# cslr_uhpi register map
Vendor: Texas Instruments
Peripheral module from a debugger description file (folder C5517).
Address unit: 16 bits
Registers are 16-bit, read-only, reset 0x0 unless marked. A register's access mark holds for its fields unless they carry their own. Offsets are as the file gives them; lines under a group give offsets from that group; [hi:lo] are bit positions; {n}, {i} and the like mark numbered series; 'fields as' and 'values as' point back to an identical list; <NAME> marks a mode.

## UHPI — Parallel port interface for accessing CPU s memory space by external host processor.
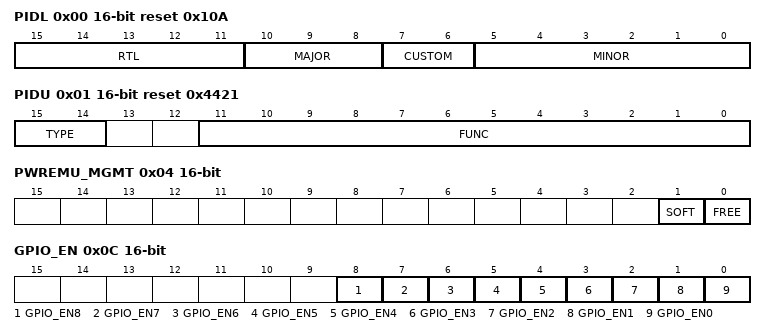
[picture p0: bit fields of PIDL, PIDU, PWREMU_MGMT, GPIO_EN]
0x00 PIDL reset 0x10A — This Register stores versioning information used to identify the specific UHPI peripheral implemented in a particular device
  [15:11] RTL — RTL Version.
  [10:8] MAJOR — Major Revision. 001b for module releases corresponding to this functional spec.
  [7:6] CUSTOM — Non-custom.
  [5:0] MINOR — Minor Revision. 001010b for module releases corresponding to this functional spec.
0x01 PIDU access not given reset 0x4421 — This Register stores versioning information used to identify the specific UHPI peripheral implemented in a particular device
  [15:14] TYPE ro — Used to distinguish between old Scheme and current. Spare bit to encode future schemes.
  [11:0] FUNC ro — Function. 421h for UHPI.
0x04 PWREMU_MGMT access not given — This Register control the operation of the peripheral during emulation suspend and / or idle states
  [1] SOFT rw — Emulation Suspend bit
    0=DISABLE (Upon emulation suspend the peripheral operation is not affected.); 1=ENABLE (Upon emulation suspend current host and Vbus operations will complete, after which the Vbus interfaces will remain in the idle state)
  [0] FREE rw — Free run mode operation bit
    0=DISABLE (SOFT bit takes effect); 1=ENABLE (Upon emulation suspend the peripheral operation will not be affected (regardless of SOFT).)
0x08 GPINT_CTRLL access not given — GPIO interrupts control Register lower
  [2] GPINT_EN rw — GPIO Interrupt Enable bit
    0=DISABLE (Enabled /HAS as a GPINT sourcing the CPU Interrupt); 1=ENABLE (Disabled /HAS as a GPINT sourcing the CPU Interrupt)
0x09 GPINT_CTRLU access not given — GPIO interrupts control Register Upper
  [2] GPINT_INV rw — GPINT Invert bit
    0=DISABLE (GPINT not inverted); 1=ENABLE (GPINT inverted)
0x0C GPIO_EN access not given — GPIO enable Register
  [8] GPIO_EN8 rw — GPIO Enable bit 8
    0=DISABLE (HD[15:8] pins will work as HPI.); 1=ENABLE (HD[15:8] pins will work as GPIO.)
  [7] GPIO_EN7 rw — GPIO Enable bit 7
    0=DISABLE (HD[7:0] pins will work as HPI.); 1=ENABLE (HD[7:0] pins will work as GPIO.)
  [6] GPIO_EN6 rw — GPIO Enable bit 6
    0=DISABLE (/HINT pin will work as HPI.); 1=ENABLE (/HINT pin will work as GPIO.)
  [5] GPIO_EN5 rw — GPIO Enable bit 5
    0=DISABLE (HRDY and /HRDY pins will work as HPI.); 1=ENABLE (HRDY and /HRDY pins will work as GPIO.)
  [4] GPIO_EN4 rw — GPIO Enable bit 4
    0=DISABLE (HHWIL pin will work as HPI.); 1=ENABLE (HHWIL pin will work as GPIO.)
  [3] GPIO_EN3 rw — GPIO Enable bit 3
    0=DISABLE (/HBE[3:0] pins will work as HPI.); 1=ENABLE (/HBE[3:0] pins will work as GPIO.)
  [2] GPIO_EN2 rw — GPIO Enable bit 2
    0=DISABLE (/HAS pin will work as HPI.); 1=ENABLE (/HAS pin will work as GPIO.)
  [1] GPIO_EN1 rw — GPIO Enable bit 1
    0=DISABLE (HCNTL[B:A] pins will work as HPI.); 1=ENABLE (HCNTL[B:A] pins will work as GPIO.)
  [0] GPIO_EN0 rw — GPIO Enable bit 0
    0=DISABLE (/HCS, /HDS1, /HDS2 and HR/W pins will work as HPI.); 1=ENABLE (/HCS, /HDS1, /HDS2 and HR/W pins will work as GPIO.)
0x10 GPIO_DIR1 rw — GPIO direction control Register
  [15:0] DIR — The DIR bits control the direction of the HD[15:0] pins when they are configured as general purpose I/O. DIRx=1 configures the HDx pin as an output and DIRx=0 configures theHDx pin as an input.
0x14 GPIO_DAT1 rw — GPIO Data Register
  [15:0] DAT — The value written in this will reflect on HD[15:0], when configured as output.And will read the logical level on the pin when configured as input.
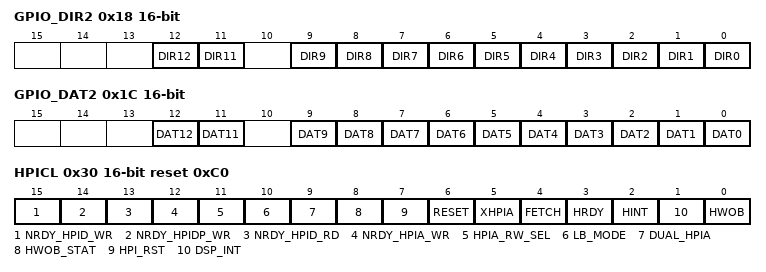
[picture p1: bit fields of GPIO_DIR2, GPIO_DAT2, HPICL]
0x18 GPIO_DIR2 access not given — GPIO direction control Register
  [12] DIR12 rw — Direction control for /HBE1 pin when configured as GPIO
    1=OUTPUT (/HBE1 pin configured as output.); 0=INPUT (/HBE1 pin configured as input.)
  [11] DIR11 rw — Direction control for /HBE0 pin when configured as GPIO
    1=OUTPUT (/HBE0 pin configured as output.); 0=INPUT (/HBE0 pin configured as input.)
  [9] DIR9 rw — Direction control for HRDY pin when configured as GPIO
    1=OUTPUT (HRDY pin configured as output.); 0=INPUT (/HRDY pin configured as input.)
  [8] DIR8 rw — Direction control for /HINT pin when configured as GPIO
    1=OUTPUT (/HINT pin configured as output.); 0=INPUT (HRDY pin configured as input.)
  [7] DIR7 rw — Direction control for HCNTLA pin when configured as GPIO
    1=OUTPUT (HCNTLA pin configured as output.); 0=INPUT (/HINT pin configured as input.)
  [6] DIR6 rw — Direction control for HCNTLB pin when configured as GPIO
    1=OUTPUT (HCNTLB pin configured as output.); 0=INPUT (HCNTLA pin configured as input.)
  [5] DIR5 rw — Direction control for HHWIL pin when configured as GPIO
    1=OUTPUT (HHWIL pin configured as output.); 0=INPUT (HCNTLB pin configured as input.)
  [4] DIR4 rw — Direction control for HR/W pin when configured as GPIO
    1=OUTPUT (HR/W pin configured as output.); 0=INPUT (HHWIL pin configured as input.)
  [3] DIR3 rw — Direction control for /HDS2 pin when configured as GPIO
    1=OUTPUT (/HDS2 pin configured as output.); 0=INPUT (HR/W pin configured as input.)
  [2] DIR2 rw — Direction control for /HDS1 pin when configured as GPIO
    1=OUTPUT (/HDS1 pin configured as output.); 0=INPUT (/HDS2 pin configured as input.)
  [1] DIR1 rw — Direction control for /HCS pin when configured as GPIO
    1=OUTPUT (/HCS pin configured as output.); 0=INPUT (/HDS1 pin configured as input.)
  [0] DIR0 rw — Direction control for /HAS pin when configured as GPIO
    1=OUTPUT (/HAS pin configured as output.); 0=INPUT (/HCS pin configured as input.)
0x1C GPIO_DAT2 access not given — GPIO Data Register
  [12] DAT12 rw — Controls the output level of the /HBE1 pin when configured as output and reads the status of /HBE1 when configured as input
    1=HIGH (/HBE1 pin is at logical high or driven high); 0=LOW (/HBE2 pin is at logical low or driven low)
  [11] DAT11 rw — Controls the output level of the /HBE0 pin when configured as output and reads the status of /HBE0 when configured as input
    1=HIGH (/HBE0 pin is at logical high or driven high); 0=LOW (/HBE1 pin is at logical low or driven low)
  [9] DAT9 rw — Controls the output level of the HRDY pin when configured as output and reads the status of HRDY when configured as input
    1=HIGH (HRDY pin is at logical high or driven high); 0=LOW (/HRDY pin is at logical low or driven low)
  [8] DAT8 rw — Controls the output level of the /HINT pin when configured as output and reads the status of /HINT when configured as input
    1=HIGH (/HINTpin is at logical high or driven high); 0=LOW (HRDY pin is at logical low or driven low)
  [7] DAT7 rw — Controls the output level of the HCNTLA pin when configured as output and reads the status of HCNTLA when configured as input
    1=HIGH (HCNTLA pin is at logical high or driven high); 0=LOW (/HINT pin is at logical low or driven low)
  [6] DAT6 rw — Controls the output level of the HCNTLB pin when configured as output and reads the status of HCNTLB when configured as input
    1=HIGH (HCNTLB pin is at logical high or driven high); 0=LOW (HCNTLA pin is at logical low or driven low)
  [5] DAT5 rw — Controls the output level of the HHWIL pin when configured as output and reads the status of HHWIL when configured as input
    1=HIGH (HHWIL pin is at logical high or driven high); 0=LOW (HCNTLB pin is at logical low or driven low)
  [4] DAT4 rw — Controls the output level of the HR/W pin when configured as output and reads the status of HR/W when configured as input
    1=HIGH (HR/W pin is at logical high or driven high); 0=LOW (HHWIL pin is at logical low or driven low)
  [3] DAT3 rw — Controls the output level of the /HDS2 pin when configured as output and reads the status of /HDS2 when configured as input
    1=HIGH (/HDS2 pin is at logical high or driven high); 0=LOW (HR/W pin is at logical low or driven low)
  [2] DAT2 rw — Controls the output level of the /HDS1 pin when configured as output and reads the status of /HDS1 when configured as input
    1=HIGH (/HDS1 pin is at logical high or driven high); 0=LOW (/HDS2 pin is at logical low or driven low)
  [1] DAT1 rw — Controls the output level of the /HCS pin when configured as output and reads the status of /HCS when configured as input
    1=HIGH (/HCS pin is at logical high or driven high); 0=LOW (/HDS1 pin is at logical low or driven low)
  [0] DAT0 rw — Controls the output level of the /HAS pin when configured as output and reads the status of /HAS when configured as input
    1=HIGH (/HAS pin is at logical high or driven high); 0=LOW (/HCS pin is at logical low or driven low)
0x30 HPICL access per field reset 0xC0 — Host Port Interface Control Register-Lower
  [15] NRDY_HPID_WR ro — HPID Non-Incrementing Write Not Ready 0: It is safe to perform a single HPID non-incrementing write because the write FIFO is empty. 1: The write FIFO is not empty or is flushing, therefore an HPID non-incrementing write would result in HRDY pin deassertion. The write data is lost or corrupted and the HPI interface could be corrupted.
    1=NRDY (The write FIFO is not empty or is flushing, therefore an HPID non-incrementing write would result in HRDY pin deassertion. The write data is lost or corrupted and the HPI interface could be corrupted.)
  [14] NRDY_HPIDP_WR ro — HPID+ Incrementing Write Not Ready 0: It is safe to perform a single HPID+ incrementing write because the write FIFO is not full. 1: The write FIFO is full. Therefore HPID+ incrementing write would result in HRDY pin deassertion. The write data is lost or corrupted and subsequent writes may be out of sync or the HPI interface could be corrupted.
    1=NRDY (The write FIFO is full. Therefore HPID+ incrementing write would result in HRDY pin deassertion. The write data is lost or corrupted and subsequent writes may be out of sync or the HPI interface could be corrupted.); 0=READY (It is safe to perform a single HPID non-incrementing write because the write FIFO is empty.)
  [13] NRDY_HPID_RD ro — HPID Read Not Ready 0: It is safe to perform a single HPID read (incrementing or non-incrementing) because the read FIFO is not empty. 1: The read FIFO is empty or flushing. Therefore any HPID read would result in HRDY pin deassertion. The read data is not guaranteed and subsequent reads may also be out of sync or the HPI interface could be corrupted.
    1=NRDY (The read FIFO is empty or flushing. Therefore any HPID read would result in HRDY pin deassertion. The read data is not guaranteed and subsequent reads may also be out of sync or the HPI interface could be corrupted.); 0=READY (It is safe to perform a single HPID+ incrementing write because the write FIFO is not full.)
  [12] NRDY_HPIA_WR ro — HPIA Write Not Ready 0: It is safe to perform a single HPIA write because any previous HPIA write has already been fully synchronized. 1: A previous HPIA write has not finished synchronizing. Therefore any HPIA write could result in HRDY pin deassertion and the HPIA value and the host interface could be corrupted.
    1=NRDY (A previous HPIA write has not finished synchronizing. Therefore any HPIA write could result in HRDY pin deassertion and the HPIA value and the host interface could be corrupted.); 0=READY (It is safe to perform a single HPID read (incrementing or non-incrementing) because the read FIFO is not empty.)
  [11] HPIA_RW_SEL ro — HPIA Register select bit, When DUAL_HPIA=1, this bit is used to select the HPIA Register to be accessed
    1=READ (HPIA-R (read address) Register selected.); 0=READY (It is safe to perform a single HPIA write because any previous HPIA write has already been fully synchronized.)
  [10] LB_MODE ro — Loop-back mode configuration bit, valid only when HOSTLESS=1
    1=ENABLE (Loopback is disabled); 0=WRITE (HPIA-W (write address) Register is selected)
  [9] DUAL_HPIA ro — Dual HPIA mode configuration bit
    1=ENABLE (Dual HPIA mode enabled); 0=DISABLE (Loopback is enabled)
  [8] HWOB_STAT ro — HWOB status. The value of the HWOB bit is also stored in this bit position
    1=ONE (The HWOB bit is one); 0=DISABLE (Dual HPIA mode disabled)
  [7] HPI_RST rw — HPI_RESET bit
    1=GENERATE (The FIFO pointers are held in reset as soon as the pending vbus transactions are complete); 0=ZERO (The HWOB bit is zero)
  [6] RESET ro — CPU core reset bit
    1=ENABLE (Reset signal to the CPU core is active); 0=CLEAR
  [5] XHPIA ro — Extended address enable.
    1=ENABLE (Extended address enabled.); 0=DISABLE (Reset signal to the CPU core is not active)
  [4] FETCH ro — Host data fetch request bit
    1=ONE; 0=DISABLE (Extended address disabled.)
  [3] HRDY ro — The logic level of the internal HRDY signal appears in this field
    1=READY (UHPI has completed the current data access); 0=ZERO
  [2] HINT rw — DSP to host interrupt
    1=GENERATE (DSP to host interrupt has been generated); 0=BUSY (UHPI has not completed the current data access)
  [1] DSP_INT rw — Host to DSP interrupt
    1=GENERATE (Host to DSP interrupt is generated); 0=CLEAR (DSP to host interrupt bit don't have any effect)
  [0] HWOB ro — Half-word Ordering Bit
    1=LSB (First half-word is least significant.); 0=CLEAR (Host to DSP interrupt is not generated)
0x34 UHPIAWL — Register stores lower address UHPI write operation
  [15:0] DIR — Register stores Lower address UHPI write operation.
0x35 UHPIAWU — Register stores upper address UHPI write operation
  [15:0] DIR — Register stores upper address UHPI write operation.
0x38 UHPIARL — Register stores Lower address UHPI Read operation
  [15:0] DIR — Register stores Lower address UHPI Read operation.
0x39 UHPIARU — Register stores Upper address UHPI Read operation
  [15:0] DIR — Register stores Upper address UHPI Read operation.
0x3C XUHPIAWL — Register stores extended lower address UHPI write operation
  [15:0] DIR — Register stores extended lower address UHPI write operation.
0x3D XUHPIAWU — Register stores extended Upper address UHPI write operation
  [15:0] DIR — Register stores extended Upper address UHPI write operation.
0x40 XUHPIARL — Register stores extended Lower address UHPI Read operation
  [15:0] DIR — Register stores extended Lower address UHPI Read operation.
0x41 XUHPIARU — Register stores extended Upper address UHPI Read operation
  [15:0] DIR — Register stores Extended Upper address UHPI Read operation.
